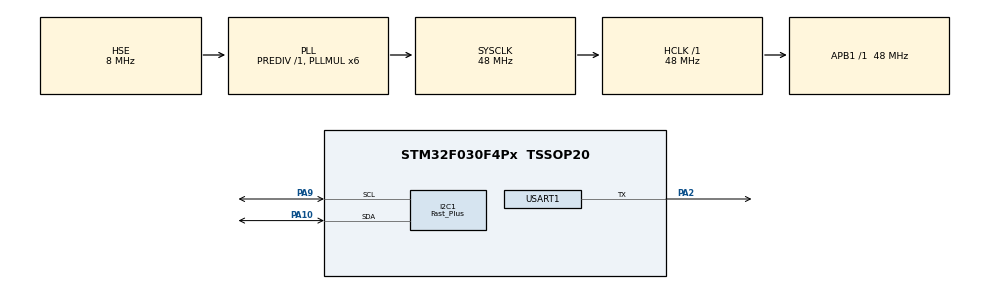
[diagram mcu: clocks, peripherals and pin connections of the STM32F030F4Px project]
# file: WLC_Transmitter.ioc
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I2C1.I2C_Speed_Mode=I2C_Fast_Plus
I2C1.Timing=0x00000001
Mcu.Family=STM32F0
Mcu.Name=STM32F030F4Px
Mcu.Package=TSSOP20
PA10.Mode=I2C
PA10.Signal=I2C1_SDA
PA13.Mode=Serial_Wire
PA13.Signal=SYS_SWDIO
PA14.Mode=Serial_Wire
PA14.Signal=SYS_SWCLK
PA2.GPIO_PuPdOD=GPIO_NOPULL
PA2.GPIO_Speed=GPIO_SPEED_FREQ_HIGH
PA2.Mode=Half_duplex(single_wire_mode)
PA2.Signal=USART1_TX
PA9.Mode=I2C
PA9.Signal=I2C1_SCL
PF0-OSC_IN.Mode=HSE-External-Oscillator
PF0-OSC_IN.Signal=RCC_OSC_IN
PF1-OSC_OUT.Mode=HSE-External-Oscillator
PF1-OSC_OUT.Signal=RCC_OSC_OUT
ProjectManager.HeapSize=0x200
ProjectManager.StackSize=0x400
ProjectManager.TargetToolchain=Makefile
RCC.AHBFreq_Value=48000000
RCC.APB1Freq_Value=48000000
RCC.APB1TimFreq_Value=48000000
RCC.HCLKFreq_Value=48000000
RCC.PLLMUL=RCC_PLL_MUL6
RCC.PLLSourceVirtual=RCC_PLLSOURCE_HSE
RCC.RTCClockSelection=RCC_RTCCLKSOURCE_HSE_DIV32
RCC.SYSCLKFreq_VALUE=48000000
RCC.SYSCLKSource=RCC_SYSCLKSOURCE_PLLCLK
RTC.AsynchPrediv=124
RTC.SynchPrediv=1999
USART1.BaudRate=115200
USART1.Mode=MODE_TX
USART1.VirtualMode-Half_duplex(single_wire_mode)=VM_ASYNC
VP_RTC_VS_RTC_Activate.Mode=RTC_Enabled
board=custom

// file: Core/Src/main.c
/* USER CODE BEGIN Header */
/**
 ******************************************************************************
 * @file           : main.c
 * @brief          : Main program body
 ******************************************************************************
 * @attention
 *
 * Copyright (c) 2024 STMicroelectronics.
 * All rights reserved.
 *
 * This software is licensed under terms that can be found in the LICENSE file
 * in the root directory of this software component.
 * If no LICENSE file comes with this software, it is provided AS-IS.
 *
 ******************************************************************************
 */
/* USER CODE END Header */
#include "main.h"
#include "gpio.h"
#include "i2c.h"
#include "rtc.h"
#include "usart.h"

/* USER CODE BEGIN Includes */

#include <stdio.h>

/* USER CODE END Includes */

/* USER CODE BEGIN PV */

RTC_TimeTypeDef time;
RTC_DateTypeDef date;
char timeString[12] = {0};
uint8_t seconds = 255;

/* USER CODE END PV */

void SystemClock_Config(void);
/* USER CODE BEGIN PFP */

uint8_t get_time(void) // 获取时间
{
  HAL_RTC_GetTime(&hrtc, &time, RTC_FORMAT_BIN);
  HAL_RTC_GetDate(&hrtc, &date, RTC_FORMAT_BIN);

  uint8_t timeChanged = time.Seconds != seconds;

  if (timeChanged) {
    seconds = time.Seconds;

    sprintf(timeString, "%.2hu:%.2hu:%.2hu", time.Hours, time.Minutes,
            time.Seconds); // 格式化时间为字符串
  }

  return timeChanged;
}

void send_time(void) // 给串口发时间
{
  HAL_UART_Transmit(&huart1, (uint8_t *)timeString, 8, 200);
}

void show_time(void) // 通过 I2C SSD1306 OLED 显示屏显示时间
{
  // SSD1306 相关代码还没准备好😒
}

/* USER CODE END PFP */

int main(void) {

  /* MCU Configuration--------------------------------------------------------*/

  /* Reset of all peripherals, Initializes the Flash interface and the Systick.
   */
  HAL_Init();

  /* Configure the system clock */
  SystemClock_Config();

  /* Initialize all configured peripherals */
  MX_GPIO_Init();
  MX_RTC_Init();
  MX_USART1_UART_Init();
  MX_I2C1_Init();

  /* Infinite loop */
  /* USER CODE BEGIN WHILE */
  while (1) {
    if (get_time()) {
      send_time();
      show_time();
    }

    /* USER CODE END WHILE */

  }
}

void SystemClock_Config(void) {
  RCC_OscInitTypeDef RCC_OscInitStruct = {0};
  RCC_ClkInitTypeDef RCC_ClkInitStruct = {0};
  RCC_PeriphCLKInitTypeDef PeriphClkInit = {0};

  /** Initializes the RCC Oscillators according to the specified parameters
   * in the RCC_OscInitTypeDef structure.
   */
  RCC_OscInitStruct.OscillatorType =
      RCC_OSCILLATORTYPE_HSI | RCC_OSCILLATORTYPE_HSE;
  RCC_OscInitStruct.HSEState = RCC_HSE_ON;
  RCC_OscInitStruct.HSIState = RCC_HSI_ON;
  RCC_OscInitStruct.HSICalibrationValue = RCC_HSICALIBRATION_DEFAULT;
  RCC_OscInitStruct.PLL.PLLState = RCC_PLL_ON;
  RCC_OscInitStruct.PLL.PLLSource = RCC_PLLSOURCE_HSE;
  RCC_OscInitStruct.PLL.PLLMUL = RCC_PLL_MUL6;
  RCC_OscInitStruct.PLL.PREDIV = RCC_PREDIV_DIV1;
  if (HAL_RCC_OscConfig(&RCC_OscInitStruct) != HAL_OK) {
    Error_Handler();
  }

  /** Initializes the CPU, AHB and APB buses clocks
   */
  RCC_ClkInitStruct.ClockType =
      RCC_CLOCKTYPE_HCLK | RCC_CLOCKTYPE_SYSCLK | RCC_CLOCKTYPE_PCLK1;
  RCC_ClkInitStruct.SYSCLKSource = RCC_SYSCLKSOURCE_PLLCLK;
  RCC_ClkInitStruct.AHBCLKDivider = RCC_SYSCLK_DIV1;
  RCC_ClkInitStruct.APB1CLKDivider = RCC_HCLK_DIV1;

  if (HAL_RCC_ClockConfig(&RCC_ClkInitStruct, FLASH_LATENCY_1) != HAL_OK) {
    Error_Handler();
  }
  PeriphClkInit.PeriphClockSelection =
      RCC_PERIPHCLK_USART1 | RCC_PERIPHCLK_I2C1 | RCC_PERIPHCLK_RTC;
  PeriphClkInit.Usart1ClockSelection = RCC_USART1CLKSOURCE_PCLK1;
  PeriphClkInit.I2c1ClockSelection = RCC_I2C1CLKSOURCE_HSI;
  PeriphClkInit.RTCClockSelection = RCC_RTCCLKSOURCE_HSE_DIV32;
  if (HAL_RCCEx_PeriphCLKConfig(&PeriphClkInit) != HAL_OK) {
    Error_Handler();
  }
}

void Error_Handler(void) {
  __disable_irq();
  while (1) {
  }
}

#ifdef USE_FULL_ASSERT
/**
 * @brief  Reports the name of the source file and the source line number
 *         where the assert_param error has occurred.
 * @param  file: pointer to the source file name
 * @param  line: assert_param error line source number
 * @retval None
 */
void assert_failed(uint8_t *file, uint32_t line) {
  /* USER CODE BEGIN 6 */
  /* User can add his own implementation to report the file name and line
     number, ex: printf("Wrong parameters value: file %s on line %d\r\n", file,
     line) */
  /* USER CODE END 6 */
}
#endif /* USE_FULL_ASSERT */
